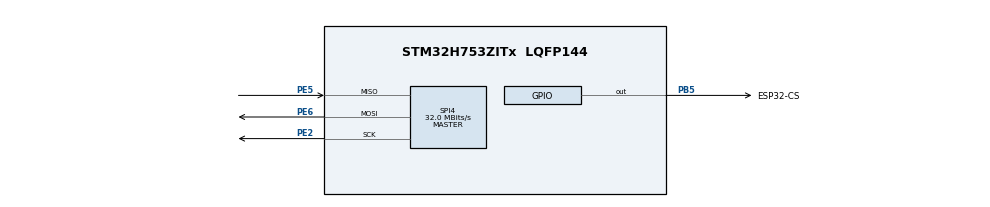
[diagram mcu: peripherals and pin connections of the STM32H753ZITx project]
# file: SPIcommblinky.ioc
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CORTEX_M7.CPU_DCache=Disabled
CORTEX_M7.CPU_ICache=Disabled
CORTEX_M7.MPU_Control=MPU_PRIVILEGED_DEFAULT
CORTEX_M7.default_mode_Activation=1
Mcu.Family=STM32H7
Mcu.Name=STM32H753ZITx
Mcu.Package=LQFP144
NUCLEO-H753ZI.BUTTON=1
NUCLEO-H753ZI.LD1=true
NUCLEO-H753ZI.LD2=true
NUCLEO-H753ZI.LD3=true
NUCLEO-H753ZI.VCP=true
NVIC.EXTI15_10_IRQn=true\:0\:0\:false\:false\:true\:false\:true\:true
NVIC.PriorityGroup=NVIC_PRIORITYGROUP_4
PA5.Signal=SPI1_SCK
PA7.Signal=SPI1_MOSI
PB5.GPIO_Label=ESP32-CS
PB5.PinState=GPIO_PIN_SET
PB5.Signal=GPIO_Output
PC14-OSC32_IN\ (OSC32_IN).Signal=RCC_OSC32_IN
PC15-OSC32_OUT\ (OSC32_OUT).Signal=RCC_OSC32_OUT
PD8.Signal=USART3_TX
PD9.Signal=USART3_RX
PE2.Mode=Full_Duplex_Master
PE2.Signal=SPI4_SCK
PE5.Mode=Full_Duplex_Master
PE5.Signal=SPI4_MISO
PE6.Mode=Full_Duplex_Master
PE6.Signal=SPI4_MOSI
PH0-OSC_IN\ (PH0).Signal=RCC_OSC_IN
PH1-OSC_OUT\ (PH1).Signal=RCC_OSC_OUT
ProjectManager.HeapSize=0x200
ProjectManager.StackSize=0x400
ProjectManager.TargetToolchain=CMake
RCC.ADCFreq_Value=129000000
RCC.APB1Freq_Value=64000000
RCC.APB2Freq_Value=64000000
RCC.APB3Freq_Value=64000000
RCC.APB4Freq_Value=64000000
RCC.CortexFreq_Value=64000000
RCC.DIVM1=4
RCC.DIVN1=9
RCC.DIVQ1=1
RCC.HCLKFreq_Value=64000000
RCC.HSE_VALUE=8000000
RCC.PLLFRACN=3072
RCC.PWR_Regulator_Voltage_Scale=PWR_REGULATOR_VOLTAGE_SCALE2
RCC.SYSCLKFreq_VALUE=64000000
RCC.USBFreq_Value=150000000
SPI4.BaudRatePrescaler=SPI_BAUDRATEPRESCALER_2
SPI4.CalculateBaudRate=32.0 MBits/s
SPI4.DataSize=SPI_DATASIZE_8BIT
SPI4.Direction=SPI_DIRECTION_2LINES
SPI4.Mode=SPI_MODE_MASTER
SPI4.VirtualType=VM_MASTER
VP_MEMORYMAP_VS_MEMORYMAP.Mode=CurAppReg
VP_NUCLEO-H753ZI_VS_BSP_COMMON.Mode=COMMON
board=NUCLEO-H753ZI

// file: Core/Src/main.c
/* USER CODE BEGIN Header */
/**
  ******************************************************************************
  * @file           : main.c
  * @brief          : Main program body
  ******************************************************************************
  * @attention
  *
  * Copyright (c) 2026 STMicroelectronics.
  * All rights reserved.
  *
  * This software is licensed under terms that can be found in the LICENSE file
  * in the root directory of this software component.
  * If no LICENSE file comes with this software, it is provided AS-IS.
  *
  ******************************************************************************
  */
/* USER CODE END Header */
#include "main.h"

COM_InitTypeDef BspCOMInit;

SPI_HandleTypeDef hspi4;

/* USER CODE BEGIN PV */
uint8_t data = 1;
/* USER CODE END PV */

void SystemClock_Config(void);
static void MPU_Config(void);
static void MX_GPIO_Init(void);
static void MX_SPI4_Init(void);

int main(void)
{

  /* MPU Configuration--------------------------------------------------------*/
  MPU_Config();

  /* MCU Configuration--------------------------------------------------------*/

  /* Reset of all peripherals, Initializes the Flash interface and the Systick. */
  HAL_Init();

  /* Configure the system clock */
  SystemClock_Config();

  /* Initialize all configured peripherals */
  MX_GPIO_Init();
  MX_SPI4_Init();

  /* Initialize leds */
  BSP_LED_Init(LED_GREEN);
  BSP_LED_Init(LED_YELLOW);
  BSP_LED_Init(LED_RED);

  /* Initialize USER push-button, will be used to trigger an interrupt each time it's pressed.*/
  BSP_PB_Init(BUTTON_USER, BUTTON_MODE_EXTI);

  /* Initialize COM1 port (115200, 8 bits (7-bit data + 1 stop bit), no parity */
  BspCOMInit.BaudRate   = 115200;
  BspCOMInit.WordLength = COM_WORDLENGTH_8B;
  BspCOMInit.StopBits   = COM_STOPBITS_1;
  BspCOMInit.Parity     = COM_PARITY_NONE;
  BspCOMInit.HwFlowCtl  = COM_HWCONTROL_NONE;
  if (BSP_COM_Init(COM1, &BspCOMInit) != BSP_ERROR_NONE)
  {
    Error_Handler();
  }

  /* Infinite loop */
  /* USER CODE BEGIN WHILE */
  HAL_GPIO_WritePin(ESP32_CS_GPIO_Port, ESP32_CS_Pin, GPIO_PIN_SET); //starts esp cs off

  while (1)
  {

    /* USER CODE END WHILE */

    /* USER CODE BEGIN 3 */
    data = 1;
    HAL_GPIO_WritePin(ESP32_CS_GPIO_Port, ESP32_CS_Pin, GPIO_PIN_RESET); //pulls cs low to start transmission
    HAL_SPI_Transmit(&hspi4, &data, 1, HAL_MAX_DELAY); //transmit data to esp32
    HAL_GPIO_WritePin(ESP32_CS_GPIO_Port, ESP32_CS_Pin, GPIO_PIN_SET); //pulls cs high to end transmission
    HAL_Delay(1000); //wait 1 second

    data = 0;
    HAL_GPIO_WritePin(ESP32_CS_GPIO_Port, ESP32_CS_Pin, GPIO_PIN_RESET); //pulls cs low to start transmission
    HAL_SPI_Transmit(&hspi4, &data, 1, HAL_MAX_DELAY);  //transmit data to esp32
    HAL_GPIO_WritePin(ESP32_CS_GPIO_Port, ESP32_CS_Pin, GPIO_PIN_SET); //pulls cs high to end transmission
    HAL_Delay(1000); //wait 1 second

  }
  /* USER CODE END 3 */
}

void SystemClock_Config(void)
{
  RCC_OscInitTypeDef RCC_OscInitStruct = {0};
  RCC_ClkInitTypeDef RCC_ClkInitStruct = {0};

  /** Supply configuration update enable
  */
  HAL_PWREx_ConfigSupply(PWR_LDO_SUPPLY);

  /** Configure the main internal regulator output voltage
  */
  __HAL_PWR_VOLTAGESCALING_CONFIG(PWR_REGULATOR_VOLTAGE_SCALE2);

  while(!__HAL_PWR_GET_FLAG(PWR_FLAG_VOSRDY)) {}

  /** Initializes the RCC Oscillators according to the specified parameters
  * in the RCC_OscInitTypeDef structure.
  */
  RCC_OscInitStruct.OscillatorType = RCC_OSCILLATORTYPE_HSI;
  RCC_OscInitStruct.HSIState = RCC_HSI_DIV1;
  RCC_OscInitStruct.HSICalibrationValue = RCC_HSICALIBRATION_DEFAULT;
  RCC_OscInitStruct.PLL.PLLState = RCC_PLL_NONE;
  if (HAL_RCC_OscConfig(&RCC_OscInitStruct) != HAL_OK)
  {
    Error_Handler();
  }

  /** Initializes the CPU, AHB and APB buses clocks
  */
  RCC_ClkInitStruct.ClockType = RCC_CLOCKTYPE_HCLK|RCC_CLOCKTYPE_SYSCLK
                              |RCC_CLOCKTYPE_PCLK1|RCC_CLOCKTYPE_PCLK2
                              |RCC_CLOCKTYPE_D3PCLK1|RCC_CLOCKTYPE_D1PCLK1;
  RCC_ClkInitStruct.SYSCLKSource = RCC_SYSCLKSOURCE_HSI;
  RCC_ClkInitStruct.SYSCLKDivider = RCC_SYSCLK_DIV1;
  RCC_ClkInitStruct.AHBCLKDivider = RCC_HCLK_DIV1;
  RCC_ClkInitStruct.APB3CLKDivider = RCC_APB3_DIV1;
  RCC_ClkInitStruct.APB1CLKDivider = RCC_APB1_DIV1;
  RCC_ClkInitStruct.APB2CLKDivider = RCC_APB2_DIV1;
  RCC_ClkInitStruct.APB4CLKDivider = RCC_APB4_DIV1;

  if (HAL_RCC_ClockConfig(&RCC_ClkInitStruct, FLASH_LATENCY_1) != HAL_OK)
  {
    Error_Handler();
  }
}

static void MX_SPI4_Init(void)
{

  /* SPI4 parameter configuration*/
  hspi4.Instance = SPI4;
  hspi4.Init.Mode = SPI_MODE_MASTER;
  hspi4.Init.Direction = SPI_DIRECTION_2LINES;
  hspi4.Init.DataSize = SPI_DATASIZE_8BIT;
  hspi4.Init.CLKPolarity = SPI_POLARITY_LOW;
  hspi4.Init.CLKPhase = SPI_PHASE_1EDGE;
  hspi4.Init.NSS = SPI_NSS_SOFT;
  hspi4.Init.BaudRatePrescaler = SPI_BAUDRATEPRESCALER_2;
  hspi4.Init.FirstBit = SPI_FIRSTBIT_MSB;
  hspi4.Init.TIMode = SPI_TIMODE_DISABLE;
  hspi4.Init.CRCCalculation = SPI_CRCCALCULATION_DISABLE;
  hspi4.Init.CRCPolynomial = 0x0;
  hspi4.Init.NSSPMode = SPI_NSS_PULSE_ENABLE;
  hspi4.Init.NSSPolarity = SPI_NSS_POLARITY_LOW;
  hspi4.Init.FifoThreshold = SPI_FIFO_THRESHOLD_01DATA;
  hspi4.Init.TxCRCInitializationPattern = SPI_CRC_INITIALIZATION_ALL_ZERO_PATTERN;
  hspi4.Init.RxCRCInitializationPattern = SPI_CRC_INITIALIZATION_ALL_ZERO_PATTERN;
  hspi4.Init.MasterSSIdleness = SPI_MASTER_SS_IDLENESS_00CYCLE;
  hspi4.Init.MasterInterDataIdleness = SPI_MASTER_INTERDATA_IDLENESS_00CYCLE;
  hspi4.Init.MasterReceiverAutoSusp = SPI_MASTER_RX_AUTOSUSP_DISABLE;
  hspi4.Init.MasterKeepIOState = SPI_MASTER_KEEP_IO_STATE_DISABLE;
  hspi4.Init.IOSwap = SPI_IO_SWAP_DISABLE;
  if (HAL_SPI_Init(&hspi4) != HAL_OK)
  {
    Error_Handler();
  }

}

static void MX_GPIO_Init(void)
{
  GPIO_InitTypeDef GPIO_InitStruct = {0};

  /* GPIO Ports Clock Enable */
  __HAL_RCC_GPIOE_CLK_ENABLE();
  __HAL_RCC_GPIOC_CLK_ENABLE();
  __HAL_RCC_GPIOH_CLK_ENABLE();
  __HAL_RCC_GPIOA_CLK_ENABLE();
  __HAL_RCC_GPIOB_CLK_ENABLE();

  /*Configure GPIO pin Output Level */
  HAL_GPIO_WritePin(ESP32_CS_GPIO_Port, ESP32_CS_Pin, GPIO_PIN_SET);

  /*Configure GPIO pins : PA5 PA7 */
  GPIO_InitStruct.Pin = GPIO_PIN_5|GPIO_PIN_7;
  GPIO_InitStruct.Mode = GPIO_MODE_AF_PP;
  GPIO_InitStruct.Pull = GPIO_NOPULL;
  GPIO_InitStruct.Speed = GPIO_SPEED_FREQ_LOW;
  GPIO_InitStruct.Alternate = GPIO_AF5_SPI1;
  HAL_GPIO_Init(GPIOA, &GPIO_InitStruct);

  /*Configure GPIO pin : ESP32_CS_Pin */
  GPIO_InitStruct.Pin = ESP32_CS_Pin;
  GPIO_InitStruct.Mode = GPIO_MODE_OUTPUT_PP;
  GPIO_InitStruct.Pull = GPIO_NOPULL;
  GPIO_InitStruct.Speed = GPIO_SPEED_FREQ_LOW;
  HAL_GPIO_Init(ESP32_CS_GPIO_Port, &GPIO_InitStruct);

}

 /* MPU Configuration */

void MPU_Config(void)
{
  MPU_Region_InitTypeDef MPU_InitStruct = {0};

  /* Disables the MPU */
  HAL_MPU_Disable();

  /** Initializes and configures the Region and the memory to be protected
  */
  MPU_InitStruct.Enable = MPU_REGION_ENABLE;
  MPU_InitStruct.Number = MPU_REGION_NUMBER0;
  MPU_InitStruct.BaseAddress = 0x0;
  MPU_InitStruct.Size = MPU_REGION_SIZE_4GB;
  MPU_InitStruct.SubRegionDisable = 0x87;
  MPU_InitStruct.TypeExtField = MPU_TEX_LEVEL0;
  MPU_InitStruct.AccessPermission = MPU_REGION_NO_ACCESS;
  MPU_InitStruct.DisableExec = MPU_INSTRUCTION_ACCESS_DISABLE;
  MPU_InitStruct.IsShareable = MPU_ACCESS_SHAREABLE;
  MPU_InitStruct.IsCacheable = MPU_ACCESS_NOT_CACHEABLE;
  MPU_InitStruct.IsBufferable = MPU_ACCESS_NOT_BUFFERABLE;

  HAL_MPU_ConfigRegion(&MPU_InitStruct);
  /* Enables the MPU */
  HAL_MPU_Enable(MPU_PRIVILEGED_DEFAULT);

}

void Error_Handler(void)
{
  __disable_irq();
  while (1)
  {
  }
}
